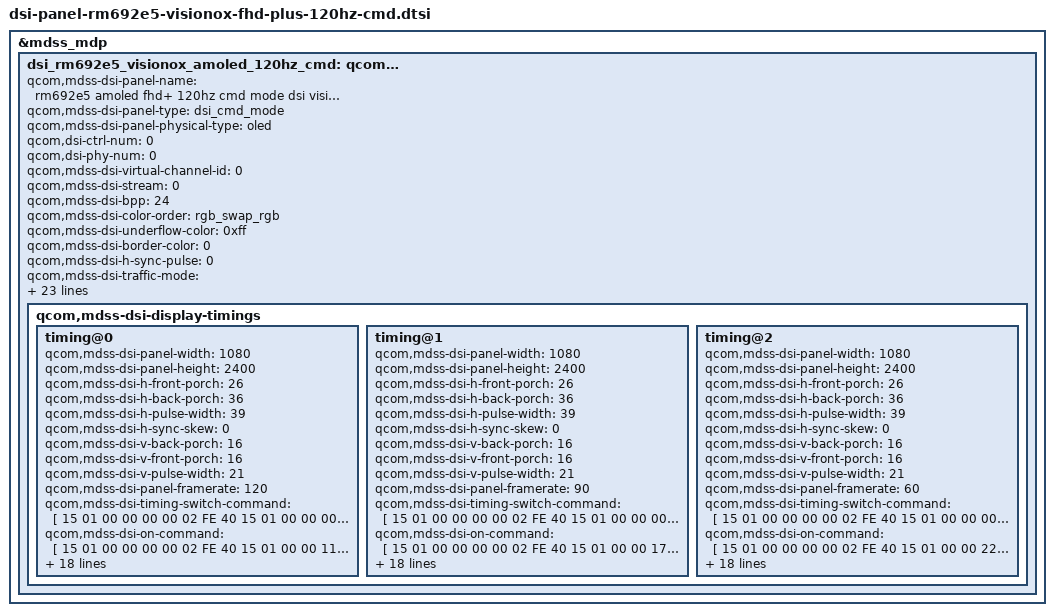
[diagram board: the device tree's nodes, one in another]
&mdss_mdp {
	dsi_rm692e5_visionox_amoled_120hz_cmd:
		qcom,mdss_dsi_rm692e5_visionox_amoled_120hz_cmd {
		qcom,mdss-dsi-panel-name =
		"rm692e5 amoled fhd+ 120hz cmd mode dsi visionox panel";
		qcom,mdss-dsi-panel-type = "dsi_cmd_mode";
		qcom,mdss-dsi-panel-physical-type = "oled";
		qcom,dsi-ctrl-num = <0>;
		qcom,dsi-phy-num = <0>;

		qcom,mdss-dsi-virtual-channel-id = <0>;
		qcom,mdss-dsi-stream = <0>;
		qcom,mdss-dsi-bpp = <24>;
		qcom,mdss-dsi-color-order = "rgb_swap_rgb";
		qcom,mdss-dsi-underflow-color = <0xff>;
		qcom,mdss-dsi-border-color = <0>;
		qcom,mdss-dsi-h-sync-pulse = <0>;
		qcom,mdss-dsi-traffic-mode = "non_burst_sync_event";
		qcom,mdss-dsi-lane-map = "lane_map_0123";
		qcom,mdss-dsi-bllp-eof-power-mode;
		qcom,mdss-dsi-bllp-power-mode;
		qcom,mdss-dsi-tx-eot-append;
		qcom,mdss-dsi-lane-0-state;
		qcom,mdss-dsi-lane-1-state;
		qcom,mdss-dsi-lane-2-state;
		qcom,mdss-dsi-lane-3-state;
		qcom,mdss-dsi-dma-trigger = "trigger_sw";
		qcom,mdss-dsi-mdp-trigger = "none";
		qcom,mdss-dsi-lp11-init;
		qcom,mdss-dsi-reset-sequence = <1 10>, <0 1>, <1 32>;
		qcom,mdss-pan-physical-width-dimension = <68>;
		qcom,mdss-pan-physical-height-dimension = <152>;
		qcom,mdss-dsi-te-pin-select = <1>;
		qcom,mdss-dsi-wr-mem-start = <0x2c>;
		qcom,mdss-dsi-wr-mem-continue = <0x3c>;
		qcom,mdss-dsi-te-dcs-command = <1>;
		qcom,mdss-dsi-te-check-enable;
		qcom,mdss-dsi-te-using-te-pin;
		qcom,fod-dim-lut = <
		/* brightness, alpha */
			1	240
			14	240
			28	240
			42	240
			56	240
			70	240
			84	240
			97	237
			111	237
			125	237
			139	237
			153	237
			167	237
			180	237
			194	237
			208	237
			222	237
			236	235
			250	235
			263	235
			277	235
			291	235
			305	235
			319	235
			333	232
			346	232
			360	232
			374	230
			388	230
			402	230
			416	230
			429	230
			443	227
			457	227
			471	227
			485	227
			499	224
			512	224
			526	224
			540	224
			554	224
			568	222
			582	222
			595	222
			609	219
			623	219
			637	219
			651	219
			665	217
			678	217
			692	217
			706	217
			720	214
			734	214
			748	214
			761	212
			775	212
			789	212
			803	212
			817	212
			831	209
			844	209
			858	209
			872	207
			886	207
			900	207
			914	207
			927	204
			941	204
			955	204
			969	201
			983	201
			997	201
			1010	201
			1024	201
			1038	199
			1052	199
			1066	199
			1080	199
			1093	196
			1107	196
			1121	194
			1135	194
			1149	194
			1163	194
			1176	194
			1190	191
			1204	191
			1218	191
			1232	191
			1246	189
			1259	189
			1273	189
			1287	189
			1301	186
			1315	186
			1329	184
			1342	184
			1356	184
			1370	184
			1384	184
			1398	181
			1412	181
			1425	181
			1439	181
			1453	181
			1467	178
			1481	178
			1495	178
			1508	176
			1522	176
			1536	176
			1550	176
			1564	173
			1578	173
			1591	173
			1605	171
			1619	171
			1633	171
			1647	171
			1661	171
			1674	168
			1688	168
			1702	168
			1716	166
			1730	166
			1744	166
			1758	163
			1771	163
			1785	163
			1799	163
			1813	161
			1827	161
			1841	161
			1854	161
			1868	158
			1882	158
			1896	158
			1910	158
			1924	156
			1937	156
			1951	153
			1965	153
			1979	153
			1993	153
			2007	150
			2020	150
			2034	148
			2048	148
			2062	148
			2076	148
			2090	145
			2103	145
			2117	145
			2131	145
			2145	145
			2159	143
			2173	143
			2186	143
			2200	143
			2214	140
			2228	140
			2242	140
			2256	140
			2269	140
			2283	138
			2297	138
			2311	135
			2325	135
			2339	135
			2352	135
			2366	133
			2380	133
			2394	133
			2408	130
			2422	130
			2435	130
			2449	130
			2463	128
			2477	128
			2491	128
			2505	128
			2518	128
			2532	125
			2546	125
			2560	125
			2574	122
			2588	122
			2601	122
			2615	122
			2629	120
			2643	120
			2657	120
			2671	117
			2684	117
			2698	117
			2712	117
			2726	115
			2740	115
			2754	115
			2767	112
			2781	112
			2795	112
			2809	112
			2823	112
			2837	110
			2850	110
			2864	110
			2878	110
			2892	110
			2906	107
			2920	107
			2933	105
			2947	105
			2961	105
			2975	105
			2989	102
			3003	102
			3016	102
			3030	102
			3044	99
			3058	99
			3072	99
			3086	99
			3099	97
			3113	97
			3127	94
			3141	94
			3155	94
			3169	94
			3182	92
			3196	92
			3210	92
			3224	92
			3238	89
			3252	89
			3265	87
			3279	87
			3293	87
			3307	87
			3321	87
			3335	84
			3348	84
			3362	84
			3376	82
			3390	82
			3404	82
			3418	79
			3431	79
			3445	79
			3459	76
			3473	76
			3487	76
			3501	76
			3515	74
		>;
		qcom,mdss-dsi-display-timings {
			timing@0 {
				qcom,mdss-dsi-panel-width = <1080>;
				qcom,mdss-dsi-panel-height = <2400>;
				qcom,mdss-dsi-h-front-porch = <26>;
				qcom,mdss-dsi-h-back-porch = <36>;
				qcom,mdss-dsi-h-pulse-width = <39>;
				qcom,mdss-dsi-h-sync-skew = <0>;
				qcom,mdss-dsi-v-back-porch = <16>;
				qcom,mdss-dsi-v-front-porch = <16>;
				qcom,mdss-dsi-v-pulse-width = <21>;
				qcom,mdss-dsi-panel-framerate = <120>;

				qcom,mdss-dsi-timing-switch-command = [
						15 01 00 00 00 00 02 FE 40
						15 01 00 00 00 00 02 BD 07
						15 01 00 00 11 00 02 FE 00
				];

				qcom,mdss-dsi-on-command = [
						15 01 00 00 00 00 02 FE 40
						15 01 00 00 11 00 02 BD 07
						15 01 00 00 00 00 02 FE D2
						15 01 00 00 00 00 02 50 11
						15 01 00 00 00 00 02 51 AB
						15 01 00 00 00 00 02 52 30
						15 01 00 00 00 00 02 53 09
						15 01 00 00 00 00 02 54 60
						15 01 00 00 00 00 02 55 04
						15 01 00 00 00 00 02 56 38
						15 01 00 00 00 00 02 58 00
						15 01 00 00 00 00 02 59 14
						15 01 00 00 00 00 02 5A 02
						15 01 00 00 00 00 02 5B 1C
						15 01 00 00 00 00 02 5C 02
						15 01 00 00 00 00 02 5D 00
						15 01 00 00 00 00 02 5E 20
						15 01 00 00 00 00 02 5F 01
						15 01 00 00 00 00 02 60 e8
						15 01 00 00 00 00 02 61 00
						15 01 00 00 00 00 02 62 07
						15 01 00 00 00 00 02 63 0C
						15 01 00 00 00 00 02 64 05
						15 01 00 00 00 00 02 65 0E
						15 01 00 00 00 00 02 66 05
						15 01 00 00 00 00 02 67 16
						15 01 00 00 00 00 02 68 18
						15 01 00 00 00 00 02 69 00
						15 01 00 00 00 00 02 6A 10
						15 01 00 00 00 00 02 6B F0
						15 01 00 00 00 00 02 6C 07
						15 01 00 00 00 00 02 6D 10
						15 01 00 00 00 00 02 6E 20
						15 01 00 00 00 00 02 6F 00
						15 01 00 00 00 00 02 70 06
						15 01 00 00 00 00 02 71 0F
						15 01 00 00 00 00 02 72 0F
						15 01 00 00 00 00 02 73 33
						15 01 00 00 00 00 02 74 0E
						15 01 00 00 00 00 02 75 1C
						15 01 00 00 00 00 02 76 2A
						15 01 00 00 00 00 02 77 38
						15 01 00 00 00 00 02 78 46
						15 01 00 00 00 00 02 79 54
						15 01 00 00 00 00 02 7A 62
						15 01 00 00 00 00 02 7B 69
						15 01 00 00 00 00 02 7C 70
						15 01 00 00 00 00 02 7D 77
						15 01 00 00 00 00 02 7E 79
						15 01 00 00 00 00 02 7F 7B
						15 01 00 00 00 00 02 80 7D
						15 01 00 00 00 00 02 81 7E
						15 01 00 00 00 00 02 82 01
						15 01 00 00 00 00 02 83 02
						15 01 00 00 00 00 02 84 22
						15 01 00 00 00 00 02 85 00
						15 01 00 00 00 00 02 86 2A
						15 01 00 00 00 00 02 87 40
						15 01 00 00 00 00 02 88 2A
						15 01 00 00 00 00 02 89 BE
						15 01 00 00 00 00 02 8A 3A
						15 01 00 00 00 00 02 8B FC
						15 01 00 00 00 00 02 8C 3A
						15 01 00 00 00 00 02 8D FA
						15 01 00 00 00 00 02 8E 3A
						15 01 00 00 00 00 02 8F F8
						15 01 00 00 00 00 02 90 3B
						15 01 00 00 00 00 02 91 38
						15 01 00 00 00 00 02 92 3B
						15 01 00 00 00 00 02 93 78
						15 01 00 00 00 00 02 94 3B
						15 01 00 00 00 00 02 95 B6
						15 01 00 00 00 00 02 96 4B
						15 01 00 00 00 00 02 97 F6
						15 01 00 00 00 00 02 98 4C
						15 01 00 00 00 00 02 99 34
						15 01 00 00 00 00 02 9A 4C
						15 01 00 00 00 00 02 9B 74
						15 01 00 00 00 00 02 9C 5C
						15 01 00 00 00 00 02 9D 74
						15 01 00 00 00 00 02 9E 8C
						15 01 00 00 00 00 02 9F F4
						15 01 00 00 00 00 02 A2 02
						15 01 00 00 00 00 02 A3 1C
						15 01 00 00 00 00 02 A4 00
						15 01 00 00 00 00 02 A5 00
						15 01 00 00 00 00 02 A6 00
						15 01 00 00 00 00 02 A7 00
						15 01 00 00 00 00 02 A9 00
						15 01 00 00 00 00 02 AA 00
						15 01 00 00 00 00 02 A0 80
						15 01 00 00 00 00 02 FE A1
						15 01 00 00 00 00 02 CD 6B
						15 01 00 00 00 00 02 CE BB
						15 01 00 00 00 00 02 FE D1
						15 01 00 00 00 00 02 B4 01
						15 01 00 00 00 00 02 FE 38
						15 01 00 00 00 00 02 17 0F
						15 01 00 00 00 00 02 18 0F
						15 01 00 00 00 00 02 FE 00
						15 01 00 00 00 00 02 FA 01
						15 01 00 00 00 00 02 C2 08
						15 01 00 00 00 00 02 35 00
						15 01 00 00 00 00 03 51 0D BB
						05 01 00 00 32 00 02 11 00
						05 01 00 00 01 00 02 29 00];
				qcom,mdss-dsi-off-command = [
						05 01 00 00 01 00 02 28 00
						05 01 00 00 01 00 02 10 00];
				qcom,mdss-dsi-on-command-state = "dsi_lp_mode";
				qcom,mdss-dsi-off-command-state = "dsi_hs_mode";

				qcom,mdss-dsi-lp1-command = [
						15 01 00 00 00 00 02 FE 00
						05 01 00 00 00 00 01 39];
				qcom,mdss-dsi-lp1-command-state = "dsi_lp_mode";
				qcom,mdss-dsi-nolp-command = [
						15 01 00 00 00 00 02 FE 00
						05 01 00 00 00 00 01 38];
				qcom,mdss-dsi-nolp-command-state = "dsi_lp_mode";

				qcom,mdss-dsi-h-sync-pulse = <0>;
				qcom,compression-mode = "dsc";
				qcom,mdss-dsc-slice-height = <20>;
				qcom,mdss-dsc-slice-width = <540>;
				qcom,mdss-dsc-slice-per-pkt = <2>;
				qcom,mdss-dsc-bit-per-component = <10>;
				qcom,mdss-dsc-bit-per-pixel = <8>;
				qcom,mdss-dsc-block-prediction-enable;
			};
			timing@1 {
				qcom,mdss-dsi-panel-width = <1080>;
				qcom,mdss-dsi-panel-height = <2400>;
				qcom,mdss-dsi-h-front-porch = <26>;
				qcom,mdss-dsi-h-back-porch = <36>;
				qcom,mdss-dsi-h-pulse-width = <39>;
				qcom,mdss-dsi-h-sync-skew = <0>;
				qcom,mdss-dsi-v-back-porch = <16>;
				qcom,mdss-dsi-v-front-porch = <16>;
				qcom,mdss-dsi-v-pulse-width = <21>;
				qcom,mdss-dsi-panel-framerate = <90>;

				qcom,mdss-dsi-timing-switch-command = [
						15 01 00 00 00 00 02 FE 40
						15 01 00 00 00 00 02 BD 06
						15 01 00 00 17 00 02 FE 00
				];

				qcom,mdss-dsi-on-command = [
						15 01 00 00 00 00 02 FE 40
						15 01 00 00 17 00 02 BD 06
						15 01 00 00 00 00 02 FE D2
						15 01 00 00 00 00 02 50 11
						15 01 00 00 00 00 02 51 AB
						15 01 00 00 00 00 02 52 30
						15 01 00 00 00 00 02 53 09
						15 01 00 00 00 00 02 54 60
						15 01 00 00 00 00 02 55 04
						15 01 00 00 00 00 02 56 38
						15 01 00 00 00 00 02 58 00
						15 01 00 00 00 00 02 59 14
						15 01 00 00 00 00 02 5A 02
						15 01 00 00 00 00 02 5B 1C
						15 01 00 00 00 00 02 5C 02
						15 01 00 00 00 00 02 5D 00
						15 01 00 00 00 00 02 5E 20
						15 01 00 00 00 00 02 5F 01
						15 01 00 00 00 00 02 60 e8
						15 01 00 00 00 00 02 61 00
						15 01 00 00 00 00 02 62 07
						15 01 00 00 00 00 02 63 0C
						15 01 00 00 00 00 02 64 05
						15 01 00 00 00 00 02 65 0E
						15 01 00 00 00 00 02 66 05
						15 01 00 00 00 00 02 67 16
						15 01 00 00 00 00 02 68 18
						15 01 00 00 00 00 02 69 00
						15 01 00 00 00 00 02 6A 10
						15 01 00 00 00 00 02 6B F0
						15 01 00 00 00 00 02 6C 07
						15 01 00 00 00 00 02 6D 10
						15 01 00 00 00 00 02 6E 20
						15 01 00 00 00 00 02 6F 00
						15 01 00 00 00 00 02 70 06
						15 01 00 00 00 00 02 71 0F
						15 01 00 00 00 00 02 72 0F
						15 01 00 00 00 00 02 73 33
						15 01 00 00 00 00 02 74 0E
						15 01 00 00 00 00 02 75 1C
						15 01 00 00 00 00 02 76 2A
						15 01 00 00 00 00 02 77 38
						15 01 00 00 00 00 02 78 46
						15 01 00 00 00 00 02 79 54
						15 01 00 00 00 00 02 7A 62
						15 01 00 00 00 00 02 7B 69
						15 01 00 00 00 00 02 7C 70
						15 01 00 00 00 00 02 7D 77
						15 01 00 00 00 00 02 7E 79
						15 01 00 00 00 00 02 7F 7B
						15 01 00 00 00 00 02 80 7D
						15 01 00 00 00 00 02 81 7E
						15 01 00 00 00 00 02 82 01
						15 01 00 00 00 00 02 83 02
						15 01 00 00 00 00 02 84 22
						15 01 00 00 00 00 02 85 00
						15 01 00 00 00 00 02 86 2A
						15 01 00 00 00 00 02 87 40
						15 01 00 00 00 00 02 88 2A
						15 01 00 00 00 00 02 89 BE
						15 01 00 00 00 00 02 8A 3A
						15 01 00 00 00 00 02 8B FC
						15 01 00 00 00 00 02 8C 3A
						15 01 00 00 00 00 02 8D FA
						15 01 00 00 00 00 02 8E 3A
						15 01 00 00 00 00 02 8F F8
						15 01 00 00 00 00 02 90 3B
						15 01 00 00 00 00 02 91 38
						15 01 00 00 00 00 02 92 3B
						15 01 00 00 00 00 02 93 78
						15 01 00 00 00 00 02 94 3B
						15 01 00 00 00 00 02 95 B6
						15 01 00 00 00 00 02 96 4B
						15 01 00 00 00 00 02 97 F6
						15 01 00 00 00 00 02 98 4C
						15 01 00 00 00 00 02 99 34
						15 01 00 00 00 00 02 9A 4C
						15 01 00 00 00 00 02 9B 74
						15 01 00 00 00 00 02 9C 5C
						15 01 00 00 00 00 02 9D 74
						15 01 00 00 00 00 02 9E 8C
						15 01 00 00 00 00 02 9F F4
						15 01 00 00 00 00 02 A2 02
						15 01 00 00 00 00 02 A3 1C
						15 01 00 00 00 00 02 A4 00
						15 01 00 00 00 00 02 A5 00
						15 01 00 00 00 00 02 A6 00
						15 01 00 00 00 00 02 A7 00
						15 01 00 00 00 00 02 A9 00
						15 01 00 00 00 00 02 AA 00
						15 01 00 00 00 00 02 A0 80
						15 01 00 00 00 00 02 FE A1
						15 01 00 00 00 00 02 CD 6B
						15 01 00 00 00 00 02 CE BB
						15 01 00 00 00 00 02 FE D1
						15 01 00 00 00 00 02 B4 01
						15 01 00 00 00 00 02 FE 38
						15 01 00 00 00 00 02 17 0F
						15 01 00 00 00 00 02 18 0F
						15 01 00 00 00 00 02 FE 00
						15 01 00 00 00 00 02 FA 01
						15 01 00 00 00 00 02 C2 08
						15 01 00 00 00 00 02 35 00
						15 01 00 00 00 00 03 51 0D BB
						05 01 00 00 32 00 02 11 00
						05 01 00 00 01 00 02 29 00];
				qcom,mdss-dsi-off-command = [
						05 01 00 00 01 00 02 28 00
						05 01 00 00 01 00 02 10 00];
				qcom,mdss-dsi-on-command-state = "dsi_lp_mode";
				qcom,mdss-dsi-off-command-state = "dsi_hs_mode";

				qcom,mdss-dsi-lp1-command = [
						15 01 00 00 00 00 02 FE 00
						05 01 00 00 00 00 01 39];
				qcom,mdss-dsi-lp1-command-state = "dsi_lp_mode";
				qcom,mdss-dsi-nolp-command = [
						15 01 00 00 00 00 02 FE 00
						05 01 00 00 00 00 01 38];
				qcom,mdss-dsi-nolp-command-state = "dsi_lp_mode";

				qcom,mdss-dsi-h-sync-pulse = <0>;
				qcom,compression-mode = "dsc";
				qcom,mdss-dsc-slice-height = <20>;
				qcom,mdss-dsc-slice-width = <540>;
				qcom,mdss-dsc-slice-per-pkt = <2>;
				qcom,mdss-dsc-bit-per-component = <10>;
				qcom,mdss-dsc-bit-per-pixel = <8>;
				qcom,mdss-dsc-block-prediction-enable;
			};
			timing@2 {
				qcom,mdss-dsi-panel-width = <1080>;
				qcom,mdss-dsi-panel-height = <2400>;
				qcom,mdss-dsi-h-front-porch = <26>;
				qcom,mdss-dsi-h-back-porch = <36>;
				qcom,mdss-dsi-h-pulse-width = <39>;
				qcom,mdss-dsi-h-sync-skew = <0>;
				qcom,mdss-dsi-v-back-porch = <16>;
				qcom,mdss-dsi-v-front-porch = <16>;
				qcom,mdss-dsi-v-pulse-width = <21>;
				qcom,mdss-dsi-panel-framerate = <60>;

				qcom,mdss-dsi-timing-switch-command = [
						15 01 00 00 00 00 02 FE 40
						15 01 00 00 00 00 02 BD 00
						15 01 00 00 22 00 02 FE 00
				];

				qcom,mdss-dsi-on-command = [
						15 01 00 00 00 00 02 FE 40
						15 01 00 00 22 00 02 BD 00
						15 01 00 00 00 00 02 FE D2
						15 01 00 00 00 00 02 50 11
						15 01 00 00 00 00 02 51 AB
						15 01 00 00 00 00 02 52 30
						15 01 00 00 00 00 02 53 09
						15 01 00 00 00 00 02 54 60
						15 01 00 00 00 00 02 55 04
						15 01 00 00 00 00 02 56 38
						15 01 00 00 00 00 02 58 00
						15 01 00 00 00 00 02 59 14
						15 01 00 00 00 00 02 5A 02
						15 01 00 00 00 00 02 5B 1C
						15 01 00 00 00 00 02 5C 02
						15 01 00 00 00 00 02 5D 00
						15 01 00 00 00 00 02 5E 20
						15 01 00 00 00 00 02 5F 01
						15 01 00 00 00 00 02 60 e8
						15 01 00 00 00 00 02 61 00
						15 01 00 00 00 00 02 62 07
						15 01 00 00 00 00 02 63 0C
						15 01 00 00 00 00 02 64 05
						15 01 00 00 00 00 02 65 0E
						15 01 00 00 00 00 02 66 05
						15 01 00 00 00 00 02 67 16
						15 01 00 00 00 00 02 68 18
						15 01 00 00 00 00 02 69 00
						15 01 00 00 00 00 02 6A 10
						15 01 00 00 00 00 02 6B F0
						15 01 00 00 00 00 02 6C 07
						15 01 00 00 00 00 02 6D 10
						15 01 00 00 00 00 02 6E 20
						15 01 00 00 00 00 02 6F 00
						15 01 00 00 00 00 02 70 06
						15 01 00 00 00 00 02 71 0F
						15 01 00 00 00 00 02 72 0F
						15 01 00 00 00 00 02 73 33
						15 01 00 00 00 00 02 74 0E
						15 01 00 00 00 00 02 75 1C
						15 01 00 00 00 00 02 76 2A
						15 01 00 00 00 00 02 77 38
						15 01 00 00 00 00 02 78 46
						15 01 00 00 00 00 02 79 54
						15 01 00 00 00 00 02 7A 62
						15 01 00 00 00 00 02 7B 69
						15 01 00 00 00 00 02 7C 70
						15 01 00 00 00 00 02 7D 77
						15 01 00 00 00 00 02 7E 79
						15 01 00 00 00 00 02 7F 7B
						15 01 00 00 00 00 02 80 7D
						15 01 00 00 00 00 02 81 7E
						15 01 00 00 00 00 02 82 01
						15 01 00 00 00 00 02 83 02
						15 01 00 00 00 00 02 84 22
						15 01 00 00 00 00 02 85 00
						15 01 00 00 00 00 02 86 2A
						15 01 00 00 00 00 02 87 40
						15 01 00 00 00 00 02 88 2A
						15 01 00 00 00 00 02 89 BE
						15 01 00 00 00 00 02 8A 3A
						15 01 00 00 00 00 02 8B FC
						15 01 00 00 00 00 02 8C 3A
						15 01 00 00 00 00 02 8D FA
						15 01 00 00 00 00 02 8E 3A
						15 01 00 00 00 00 02 8F F8
						15 01 00 00 00 00 02 90 3B
						15 01 00 00 00 00 02 91 38
						15 01 00 00 00 00 02 92 3B
						15 01 00 00 00 00 02 93 78
						15 01 00 00 00 00 02 94 3B
						15 01 00 00 00 00 02 95 B6
						15 01 00 00 00 00 02 96 4B
						15 01 00 00 00 00 02 97 F6
						15 01 00 00 00 00 02 98 4C
						15 01 00 00 00 00 02 99 34
						15 01 00 00 00 00 02 9A 4C
						15 01 00 00 00 00 02 9B 74
						15 01 00 00 00 00 02 9C 5C
						15 01 00 00 00 00 02 9D 74
						15 01 00 00 00 00 02 9E 8C
						15 01 00 00 00 00 02 9F F4
						15 01 00 00 00 00 02 A2 02
						15 01 00 00 00 00 02 A3 1C
						15 01 00 00 00 00 02 A4 00
						15 01 00 00 00 00 02 A5 00
						15 01 00 00 00 00 02 A6 00
						15 01 00 00 00 00 02 A7 00
						15 01 00 00 00 00 02 A9 00
						15 01 00 00 00 00 02 AA 00
						15 01 00 00 00 00 02 A0 80
						15 01 00 00 00 00 02 FE A1
						15 01 00 00 00 00 02 CD 6B
						15 01 00 00 00 00 02 CE BB
						15 01 00 00 00 00 02 FE D1
						15 01 00 00 00 00 02 B4 01
						15 01 00 00 00 00 02 FE 38
						15 01 00 00 00 00 02 17 0F
						15 01 00 00 00 00 02 18 0F
						15 01 00 00 00 00 02 FE 00
						15 01 00 00 00 00 02 FA 01
						15 01 00 00 00 00 02 C2 08
						15 01 00 00 00 00 02 35 00
						15 01 00 00 00 00 03 51 0D BB
						05 01 00 00 32 00 02 11 00
						05 01 00 00 01 00 02 29 00];
				qcom,mdss-dsi-off-command = [
						05 01 00 00 01 00 02 28 00
						05 01 00 00 01 00 02 10 00];
				qcom,mdss-dsi-on-command-state = "dsi_lp_mode";
				qcom,mdss-dsi-off-command-state = "dsi_hs_mode";

				qcom,mdss-dsi-lp1-command = [
						15 01 00 00 00 00 02 FE 00
						05 01 00 00 00 00 01 39];
				qcom,mdss-dsi-lp1-command-state = "dsi_lp_mode";
				qcom,mdss-dsi-nolp-command = [
						15 01 00 00 00 00 02 FE 00
						05 01 00 00 00 00 01 38];
				qcom,mdss-dsi-nolp-command-state = "dsi_lp_mode";

				qcom,mdss-dsi-h-sync-pulse = <0>;
				qcom,compression-mode = "dsc";
				qcom,mdss-dsc-slice-height = <20>;
				qcom,mdss-dsc-slice-width = <540>;
				qcom,mdss-dsc-slice-per-pkt = <2>;
				qcom,mdss-dsc-bit-per-component = <10>;
				qcom,mdss-dsc-bit-per-pixel = <8>;
				qcom,mdss-dsc-block-prediction-enable;
			};
		};
	};
};
